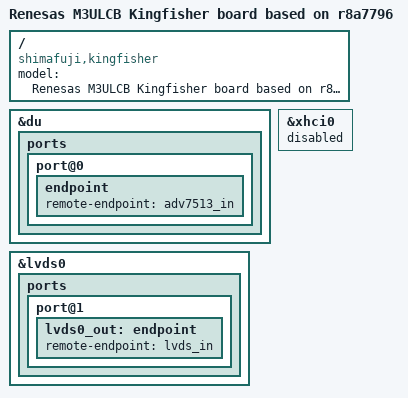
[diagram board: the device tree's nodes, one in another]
// SPDX-License-Identifier: GPL-2.0
/*
 * Device Tree Source for the M3ULCB Kingfisher board
 *
 * Copyright (C) 2017 Renesas Electronics Corp.
 * Copyright (C) 2017 Cogent Embedded, Inc.
 */

#include "r8a7796-m3ulcb.dts"
#include "ulcb-kf.dtsi"

/ {
	model = "Renesas M3ULCB Kingfisher board based on r8a7796";
	compatible = "shimafuji,kingfisher", "renesas,m3ulcb",
		     "renesas,r8a7796";
};

&du {
	ports {
		port@0 {
			endpoint {
				remote-endpoint = <&adv7513_in>;
			};
		};
	};
};

&lvds0 {
	status = "okay";

	ports {
		port@1 {
			lvds0_out: endpoint {
				remote-endpoint = <&lvds_in>;
			};
		};
	};
};

&xhci0 {
	status = "disabled";
};
